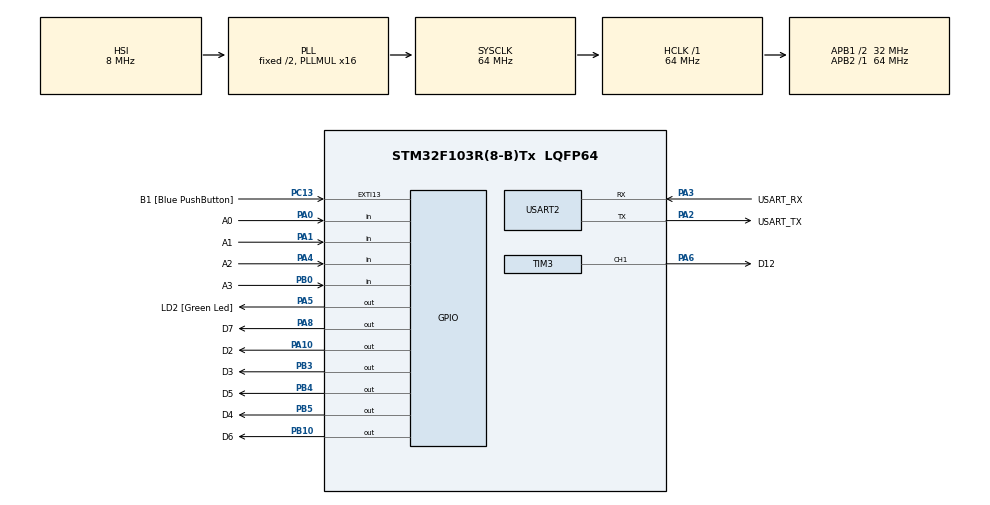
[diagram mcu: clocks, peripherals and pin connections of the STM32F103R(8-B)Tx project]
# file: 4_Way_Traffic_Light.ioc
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Mcu.Family=STM32F1
Mcu.Name=STM32F103R(8-B)Tx
Mcu.Package=LQFP64
NVIC.EXTI15_10_IRQn=true\:0\:0\:false\:false\:true\:true\:true\:true
NVIC.PriorityGroup=NVIC_PRIORITYGROUP_4
NVIC.TIM2_IRQn=true\:0\:0\:false\:false\:true\:true\:true\:true
PA0-WKUP.GPIO_Label=A0
PA0-WKUP.Signal=GPIO_Input
PA1.GPIO_Label=A1
PA1.Signal=GPIO_Input
PA10.GPIO_Label=D2
PA10.Signal=GPIO_Output
PA13.GPIO_Label=TMS
PA13.Mode=Serial_Wire
PA13.Signal=SYS_JTMS-SWDIO
PA14.GPIO_Label=TCK
PA14.Mode=Serial_Wire
PA14.Signal=SYS_JTCK-SWCLK
PA2.GPIO_Label=USART_TX
PA2.GPIO_Mode=GPIO_MODE_AF_PP
PA2.GPIO_PuPd=GPIO_NOPULL
PA2.GPIO_Speed=GPIO_SPEED_FREQ_LOW
PA2.Mode=Asynchronous
PA2.Signal=USART2_TX
PA3.GPIO_Label=USART_RX
PA3.GPIO_Mode=GPIO_MODE_AF_PP
PA3.GPIO_PuPd=GPIO_NOPULL
PA3.GPIO_Speed=GPIO_SPEED_FREQ_LOW
PA3.Mode=Asynchronous
PA3.Signal=USART2_RX
PA4.GPIO_Label=A2
PA4.Signal=GPIO_Input
PA5.GPIO_Label=LD2 [Green Led]
PA5.GPIO_ModeDefaultOutputPP=GPIO_MODE_OUTPUT_PP
PA5.GPIO_PuPd=GPIO_NOPULL
PA5.GPIO_Speed=GPIO_SPEED_FREQ_LOW
PA5.Signal=GPIO_Output
PA6.GPIO_Label=D12
PA6.Signal=S_TIM3_CH1
PA8.GPIO_Label=D7
PA8.Signal=GPIO_Output
PB0.GPIO_Label=A3
PB0.Signal=GPIO_Input
PB10.GPIO_Label=D6
PB10.Signal=GPIO_Output
PB3.GPIO_Label=D3
PB3.Signal=GPIO_Output
PB4.GPIO_Label=D5
PB4.Signal=GPIO_Output
PB5.GPIO_Label=D4
PB5.Signal=GPIO_Output
PC13-TAMPER-RTC.GPIO_Label=B1 [Blue PushButton]
PC13-TAMPER-RTC.GPIO_PuPd=GPIO_NOPULL
PC13-TAMPER-RTC.Signal=GPXTI13
PC14-OSC32_IN.Mode=LSE-External-Oscillator
PC14-OSC32_IN.Signal=RCC_OSC32_IN
PC15-OSC32_OUT.Mode=LSE-External-Oscillator
PC15-OSC32_OUT.Signal=RCC_OSC32_OUT
PD0-OSC_IN.Mode=HSE-External-Clock-Source
PD0-OSC_IN.Signal=RCC_OSC_IN
PD1-OSC_OUT.Mode=HSE-External-Clock-Source
PD1-OSC_OUT.Signal=RCC_OSC_OUT
ProjectManager.HeapSize=0x200
ProjectManager.StackSize=0x400
ProjectManager.TargetToolchain=STM32CubeIDE
RCC.AHBFreq_Value=64000000
RCC.APB1CLKDivider=RCC_HCLK_DIV2
RCC.APB1Freq_Value=32000000
RCC.APB1TimFreq_Value=64000000
RCC.APB2Freq_Value=64000000
RCC.APB2TimFreq_Value=64000000
RCC.HCLKFreq_Value=64000000
RCC.PLLMUL=RCC_PLL_MUL16
RCC.RTCClockSelection=RCC_RTCCLKSOURCE_LSE
RCC.SYSCLKFreq_VALUE=64000000
RCC.SYSCLKSource=RCC_SYSCLKSOURCE_PLLCLK
RCC.USBFreq_Value=64000000
SH.S_TIM3_CH1.0=TIM3_CH1,PWM Generation1 CH1
TIM2.Period=9999
TIM2.Prescaler=63
TIM3.Channel-PWM\ Generation1\ CH1=TIM_CHANNEL_1
TIM3.Period=999
TIM3.Prescaler=63
USART2.VirtualMode=VM_ASYNC
VP_TIM2_VS_ClockSourceINT.Mode=Internal
VP_TIM3_VS_ClockSourceINT.Mode=Internal
board=NUCLEO-F103RB

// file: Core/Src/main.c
/* USER CODE BEGIN Header */
/**
  ******************************************************************************
  * @file           : main.c
  * @brief          : Main program body
  ******************************************************************************
  * @attention
  *
  * Copyright (c) 2022 STMicroelectronics.
  * All rights reserved.
  *
  * This software is licensed under terms that can be found in the LICENSE file
  * in the root directory of this software component.
  * If no LICENSE file comes with this software, it is provided AS-IS.
  *
  ******************************************************************************
  */
/* USER CODE END Header */
#include "main.h"
#include "tim.h"
#include "usart.h"
#include "gpio.h"

/* USER CODE BEGIN Includes */
#include "global.h"
#include "sched.h"
#include "fsm_for_multi_mode.h"
#include "fsm_for_pedestrian.h"
/* USER CODE END Includes */

void SystemClock_Config(void);
void UpdateTimer(void);

int main(void)
{

  /* MCU Configuration--------------------------------------------------------*/

  /* Reset of all peripherals, Initializes the Flash interface and the Systick. */
  HAL_Init();

  /* Configure the system clock */
  SystemClock_Config();

  /* Initialize all configured peripherals */
  MX_GPIO_Init();
  MX_USART2_UART_Init();
  MX_TIM3_Init();
  MX_TIM2_Init();
  /* USER CODE BEGIN 2 */
  HAL_TIM_Base_Start_IT(&htim2);
  HAL_TIM_PWM_Start(&htim3, TIM_CHANNEL_1);

  // SCH_Add_Task(&timerRun, 0, 10);
  SCH_Add_Task(&UpdateTimer, 0, 10);
  SCH_Add_Task(&buttonRead, 10, 10);
  SCH_Add_Task(&fsm_multi_mode_run, 20, 10);
  SCH_Add_Task(&fsm_for_pedestrian, 30, 10);
  /* USER CODE END 2 */

  /* Infinite loop */
  /* USER CODE BEGIN WHILE */
  while (1)
  {
	SCH_Dispatch_Tasks();
    /* USER CODE END WHILE */

  }
}

void UpdateTimer(void) {
  timerBreath(&timer1);
  timerBreath(&timer2);
  timerBreath(&timer3);
}

void SystemClock_Config(void)
{
  RCC_OscInitTypeDef RCC_OscInitStruct = {0};
  RCC_ClkInitTypeDef RCC_ClkInitStruct = {0};

  /** Initializes the RCC Oscillators according to the specified parameters
  * in the RCC_OscInitTypeDef structure.
  */
  RCC_OscInitStruct.OscillatorType = RCC_OSCILLATORTYPE_HSI;
  RCC_OscInitStruct.HSIState = RCC_HSI_ON;
  RCC_OscInitStruct.HSICalibrationValue = RCC_HSICALIBRATION_DEFAULT;
  RCC_OscInitStruct.PLL.PLLState = RCC_PLL_ON;
  RCC_OscInitStruct.PLL.PLLSource = RCC_PLLSOURCE_HSI_DIV2;
  RCC_OscInitStruct.PLL.PLLMUL = RCC_PLL_MUL16;
  if (HAL_RCC_OscConfig(&RCC_OscInitStruct) != HAL_OK)
  {
    Error_Handler();
  }

  /** Initializes the CPU, AHB and APB buses clocks
  */
  RCC_ClkInitStruct.ClockType = RCC_CLOCKTYPE_HCLK|RCC_CLOCKTYPE_SYSCLK
                              |RCC_CLOCKTYPE_PCLK1|RCC_CLOCKTYPE_PCLK2;
  RCC_ClkInitStruct.SYSCLKSource = RCC_SYSCLKSOURCE_PLLCLK;
  RCC_ClkInitStruct.AHBCLKDivider = RCC_SYSCLK_DIV1;
  RCC_ClkInitStruct.APB1CLKDivider = RCC_HCLK_DIV2;
  RCC_ClkInitStruct.APB2CLKDivider = RCC_HCLK_DIV1;

  if (HAL_RCC_ClockConfig(&RCC_ClkInitStruct, FLASH_LATENCY_2) != HAL_OK)
  {
    Error_Handler();
  }
}

/* USER CODE BEGIN 4 */
void HAL_TIM_PeriodElapsedCallback(TIM_HandleTypeDef* htim)
{
	SCH_Update();
}
/* USER CODE END 4 */

void Error_Handler(void)
{
  __disable_irq();
  while (1)
  {
  }
}
